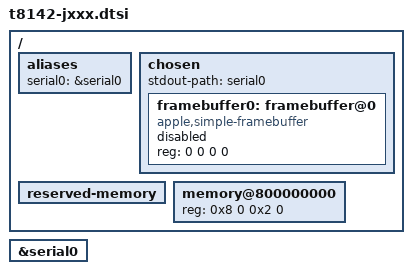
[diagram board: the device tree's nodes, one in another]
// SPDX-License-Identifier: GPL-2.0+ OR MIT
/*
 * Apple M5 MacBook Pro (M5, 2025)
 *
 * This file contains parts common to all Apple M5 devices using the t8142.
 *
 * target-type: J704
 *
 * Copyright The Asahi Linux Contributors
 */

/ {
	aliases {
		serial0 = &serial0;
	};

	chosen {
		#address-cells = <2>;
		#size-cells = <2>;
		ranges;

		stdout-path = "serial0";

		framebuffer0: framebuffer@0 {
			compatible = "apple,simple-framebuffer", "simple-framebuffer";
			reg = <0 0 0 0>; /* To be filled by loader */
			/* Format properties will be added by loader */
			status = "disabled";
		};
	};

	reserved-memory {
		#address-cells = <2>;
		#size-cells = <2>;
		ranges;
		/* To be filled by loader */
	};

	memory@800000000 {
		device_type = "memory";
		reg = <0x8 0 0x2 0>; /* To be filled by loader */
	};
};

&serial0 {
	status = "okay";
};
